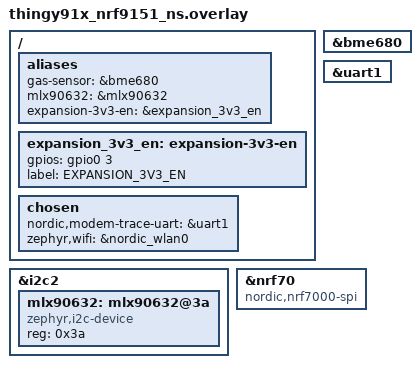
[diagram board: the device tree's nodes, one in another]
/*
 * Copyright (c) 2024 Nordic Semiconductor ASA
 *
 * SPDX-License-Identifier: LicenseRef-Nordic-5-Clause
 */

#include <thingy91x_wifi.dtsi>

&bme680 {
	status = "okay";
};

/ {
	aliases {
		gas-sensor = &bme680;
		mlx90632 = &mlx90632;
		expansion-3v3-en = &expansion_3v3_en;
	};

	expansion_3v3_en: expansion-3v3-en {
		gpios = <&gpio0 3 GPIO_ACTIVE_HIGH>;
		label = "EXPANSION_3V3_EN";
		status = "okay";
	};

	chosen {
		nordic,modem-trace-uart = &uart1;
		zephyr,wifi = &nordic_wlan0;
	};
};

&uart1 {
	status = "okay";
};

&i2c2 {
	mlx90632: mlx90632@3a {
		compatible = "zephyr,i2c-device";
		reg = <0x3a>;
	};
};


/* Switch to nrf7000 emulation so that scan-only mode is used. */
&nrf70 {
	compatible = "nordic,nrf7000-spi";
};
